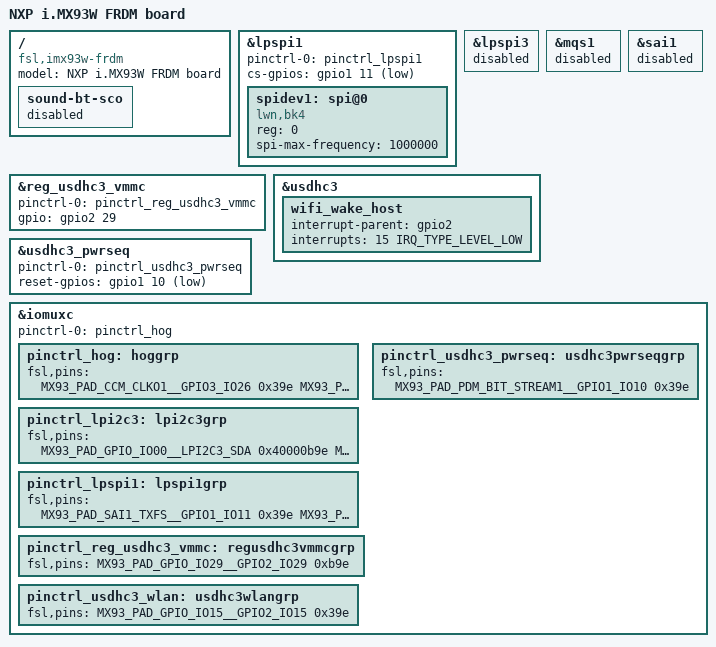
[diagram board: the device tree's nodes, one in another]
// SPDX-License-Identifier: (GPL-2.0+ OR MIT)
/*
 * Copyright 2026 NXP
 */

#include "imx93-11x11-frdm.dts"

/ {
	model = "NXP i.MX93W FRDM board";
	compatible = "fsl,imx93w-frdm", "fsl,imx93";

	/delete-node/ sound-mqs;

	sound-bt-sco {
		status = "disabled";
	};
};

&lpspi1 {
	pinctrl-names = "default";
	pinctrl-0 = <&pinctrl_lpspi1>;
	cs-gpios = <&gpio1 11 GPIO_ACTIVE_LOW>;
	status = "okay";

	spidev1: spi@0 {
		reg = <0>;
		compatible = "lwn,bk4";
		spi-max-frequency = <1000000>;
	};
};

&lpspi3 {
	status = "disabled";
};

&mqs1 {
	status = "disabled";
};

&reg_usdhc3_vmmc {
	pinctrl-0 = <&pinctrl_reg_usdhc3_vmmc>;
	pinctrl-names = "default";
	gpio = <&gpio2 29 GPIO_ACTIVE_HIGH>;
};

&sai1 {
	status = "disabled";
};

&usdhc3 {
	wifi_wake_host {
		interrupt-parent = <&gpio2>;
		interrupts = <15 IRQ_TYPE_LEVEL_LOW>;
	};
};

&usdhc3_pwrseq {
	pinctrl-0 = <&pinctrl_usdhc3_pwrseq>;
	pinctrl-names = "default";
	reset-gpios = <&gpio1 10 GPIO_ACTIVE_LOW>;
};

&iomuxc {
	pinctrl-names = "default";
	pinctrl-0 = <&pinctrl_hog>;

	pinctrl_hog: hoggrp {
		fsl,pins = <
			MX93_PAD_CCM_CLKO1__GPIO3_IO26			0x39e
			MX93_PAD_GPIO_IO28__GPIO2_IO28			0x39e
		>;
	};

	pinctrl_lpi2c3: lpi2c3grp {
		fsl,pins = <
			MX93_PAD_GPIO_IO00__LPI2C3_SDA			0x40000b9e
			MX93_PAD_GPIO_IO01__LPI2C3_SCL			0x40000b9e
		>;
	};

	pinctrl_lpspi1: lpspi1grp {
		fsl,pins = <
			MX93_PAD_SAI1_TXFS__GPIO1_IO11			0x39e
			MX93_PAD_SAI1_TXC__LPSPI1_SIN			0x39e
			MX93_PAD_SAI1_RXD0__LPSPI1_SOUT			0x39e
			MX93_PAD_SAI1_TXD0__LPSPI1_SCK			0x39e
		>;
	};

	pinctrl_reg_usdhc3_vmmc: regusdhc3vmmcgrp {
		fsl,pins = <
			/*
			 * Enable open drain and internal pull-up to allow the IW610 JTAG
			 * connector to control the PDn status.
			 */
			MX93_PAD_GPIO_IO29__GPIO2_IO29			0xb9e
		>;
	};

	pinctrl_usdhc3_pwrseq: usdhc3pwrseqgrp {
		fsl,pins = <
			MX93_PAD_PDM_BIT_STREAM1__GPIO1_IO10		0x39e
		>;
	};

	pinctrl_usdhc3_wlan: usdhc3wlangrp {
		fsl,pins = <
			MX93_PAD_GPIO_IO15__GPIO2_IO15			0x39e
		>;
	};
};
